AUTOSAR XML (schema 00051)
package /MyReceivingSWC
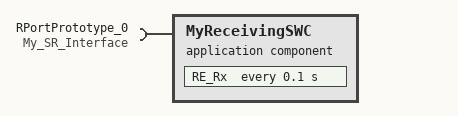
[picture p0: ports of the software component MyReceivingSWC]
  application sw component type MyReceivingSWC
    require port RPortPrototype_0: required-interface=My_SR_Interface
    behavior RxSwcInternalBehavior: data-type-mapping=MyDataTypeMappingSet, supports-multiple-instantiation=true
      timing event TE_RX: start-on-event=RE_Rx, period=0.1
      per instance memory PIM_01: init-value=0, base-type=boolean, type=boolean, type-definition=boolean
      per instance memory PIM_02: init-value=1, base-type=uint8, type=uint8, type-definition=uint8
      runnable RE_Rx: symbol=RE_Rx_func
        data-read-access:
          access DRA_DE_MyDataElement_0: accessed-variable=RPortPrototype_0.DE_MyDataElement
      swc service dependency Srv_NvM_0: category=NV_BLOCK_COMPONENT, assigned-datas=role-based-data-assignment={role=ramBlock, used-pim=PIM_01}
        service-needs:
          nv block needs NvM_Needs_0: ram-block-status-control=API, reliability=NO-PROTECTION, restore-at-start=true, store-at-shutdown=true, writing-priority=LOW
      swc service dependency Srv_NvM_1: category=NV_BLOCK_COMPONENT, assigned-datas=role-based-data-assignment={role=ramBlock, used-pim=PIM_02}
        service-needs:
          nv block needs NvM_Needs_1: restore-at-start=true, store-at-shutdown=true
